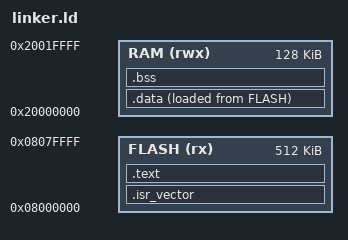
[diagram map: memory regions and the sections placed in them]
ENTRY(Reset_Handler)

MEMORY
{
    FLASH (rx)  : ORIGIN = 0x08000000, LENGTH = 512K
    RAM   (rwx) : ORIGIN = 0x20000000, LENGTH = 128K
}

_stack_top = ORIGIN(RAM) + LENGTH(RAM);

SECTIONS
{
    .isr_vector :
    {
        KEEP(*(.isr_vector))
    } > FLASH

    .text :
    {
        *(.text*)
        *(.rodata*)
    } > FLASH

    .data :
    {
        _data_start = .;
        *(.data*)
        _data_end = .;
    } > RAM AT > FLASH

    _data_load = LOADADDR(.data);

    .bss :
    {
        _bss_start = .;
        *(.bss*)
        *(COMMON)
        _bss_end = .;
    } > RAM
}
